# CAM_CM_CORE register map
Vendor: Texas Instruments
Peripheral module from a debugger description file (folder omap5430_ES2_PUBLIC).
Registers are 32-bit, access per field, reset 0x70000 unless marked. A register's access mark holds for its fields unless they carry their own. Offsets are as the file gives them; lines under a group give offsets from that group; [hi:lo] are bit positions; {n}, {i} and the like mark numbered series; 'fields as' and 'values as' point back to an identical list; <NAME> marks a mode.

## CAM_CM_CORE
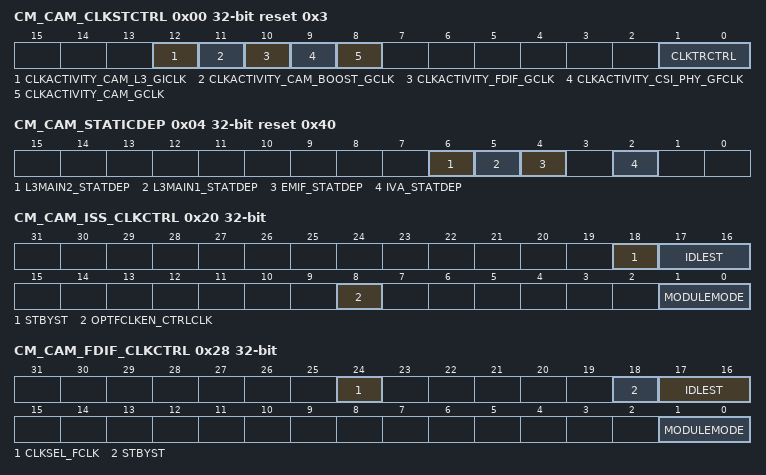
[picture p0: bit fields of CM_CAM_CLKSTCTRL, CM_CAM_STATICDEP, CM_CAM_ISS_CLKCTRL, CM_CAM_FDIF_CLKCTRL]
0x00 CM_CAM_CLKSTCTRL reset 0x3 — This register enables the domain power state transition. It controls the HW supervised domain power state transition between ON-ACTIVE and ON-INACTIVE states. It also holds 1 status bit per clock input of the domain.
  [12] CLKACTIVITY_CAM_L3_GICLK ro — This field indicates the state of the CAM_L3_GICLK clock input of the domain. [warm reset insensitive] read 0x0: Corresponding clock is definitely gated read 0x1: Corresponding clock is running or gating/ungating transition is on-going
  [11] CLKACTIVITY_CAM_BOOST_GCLK ro — This field indicates the state of the CAM_BOOST_GCLK clock input of the domain. [warm reset insensitive] read 0x0: Corresponding clock is definitely gated read 0x1: Corresponding clock is running or gating/ungating transition is on-going
  [10] CLKACTIVITY_FDIF_GCLK ro — This field indicates the state of the FDIF_GCLK clock input of the domain. [warm reset insensitive]
    0=Inact (Corresponding clock is definitely gated); 1=Act (Corresponding clock is running or gating/ungating transition is on-going)
  [9] CLKACTIVITY_CSI_PHY_GFCLK ro — This field indicates the state of the CSI_PHY_GFCLK clock input of the domain. [warm reset insensitive]
    values as CLKACTIVITY_FDIF_GCLK
  [8] CLKACTIVITY_CAM_GCLK ro — This field indicates the state of the CAM_GCLK clock input of the domain. [warm reset insensitive]
    values as CLKACTIVITY_FDIF_GCLK
  [1:0] CLKTRCTRL rw — Controls the clock state transition of the CAM clock domain.
    0=NO_SLEEP (NO_SLEEP: Sleep transition cannot be initiated. Wakeup transition may however occur.); 1=SW_SLEEP (SW_SLEEP: Start a software forced sleep transition on the domain.); 2=SW_WKUP (SW_WKUP: Start a software forced wake-up transition on the domain.); 3=HW_AUTO (HW_AUTO: Automatic transition is enabled. Sleep and wakeup transition are based upon hardware conditions.)
0x04 CM_CAM_STATICDEP reset 0x40 — This register controls the static domain depedencies from CAM domain towards 'target' domains. It is relevant only for domain having system initiator(s).
  [6] L3MAIN2_STATDEP ro — Static dependency towards L3_MAIN2 clock domain
    1=Enabled (Dependency is enabled)
  [5] L3MAIN1_STATDEP rw — Static dependency towards L3_MAIN1 clock domain
    0=Disabled (Dependency is disabled); 1=Enabled (Dependency is enabled)
  [4] EMIF_STATDEP rw — Static dependency towards EMIF clock domain
    values as L3MAIN1_STATDEP
  [2] IVA_STATDEP rw — Static dependency towards IVA clock domain
    values as L3MAIN1_STATDEP
0x08 CM_CAM_DYNAMICDEP ro reset 0x0 — This register controls the dynamic domain depedencies from CAM domain towards 'target' domains. It is relevant only for domain having INTRCONN master port(s).
  [6] L3MAIN2_DYNDEP — Dynamic dependency towards L3_MAIN2 clock domain
    0=Disabled (Dependency is disabled)
0x20 CM_CAM_ISS_CLKCTRL — This register manages the ISS clocks.
  [18] STBYST ro — Module standby status. [warm reset insensitive]
    0=Func (Module is functional (not in standby)); 1=Standby (Module is in standby)
  [17:16] IDLEST ro — Module idle status. [warm reset insensitive]
    0=Func (Module is fully functional, including INTRCONN); 1=Trans (Module is performing transition: wakeup, or sleep, or sleep abortion); 2=Idle (Module is in Idle mode (only INTRCONN part). It is functional if using separate functional clock); 3=Disable (Module is disabled and cannot be accessed)
  [8] OPTFCLKEN_CTRLCLK rw — Optional functional clock control for CSI_PHY_GFCLK 96Mhz clock.
    0=FCLK_DIS (Optional functional clock is disabled); 1=FCLK_EN (Optional functional clock is enabled)
  [1:0] MODULEMODE rw — Control the way mandatory clocks are managed.
    0=DISABLED (Module is disable by SW. Any INTRCONN access to module results in an error, except if resulting from a module wakeup (asynchronous wakeup).); 2=ENABLE (Module is explicitly enabled. Interface clock (if not used for functions) may be gated according to the clock domain state. Functional clocks are guarantied to stay present. As long as in this configuration, power domain sleep transition cannot happen.)
0x28 CM_CAM_FDIF_CLKCTRL — This register manages the FDIF clocks.
  [24] CLKSEL_FCLK rw — Select the ration of FDIF_FCLK to FUNC_256M_CLK
    0=DIV1 (FDIF_CLK is divide by 1 of FUNC_256M_CLK, to be used for OPP_NOM); 1=DIV2 (FDIF_CLK is divide by 2 of FUNC_256M_CLK, to be used for OPP_LOW)
  [18] STBYST ro — Module standby status. [warm reset insensitive]
    values as CM_CAM_ISS_CLKCTRL.STBYST
  [17:16] IDLEST ro — Module idle status. [warm reset insensitive]
    values as CM_CAM_ISS_CLKCTRL.IDLEST
  [1:0] MODULEMODE rw — Control the way mandatory clocks are managed.
    0=DISABLED (Module is disable by SW. Any INTRCONN access to module results in an error, except if resulting from a module wakeup (asynchronous wakeup).); 2=ENABLE (Module is explicitly enabled. Interface clock (if not used for functions) may be gated according to the clock domain state. Functional clocks are guaranted to stay present. As long as in this configuration, power domain sleep transition cannot happen.)
